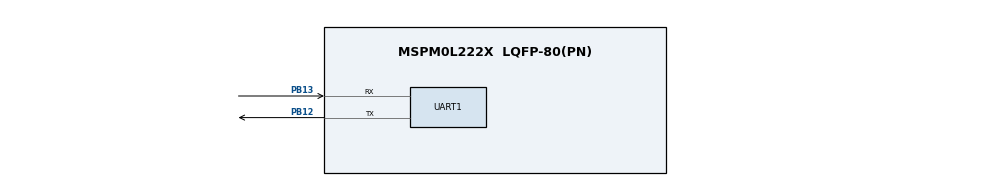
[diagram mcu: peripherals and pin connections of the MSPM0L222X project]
/**
 * @cliArgs --device "MSPM0L222X" --part "Default" --package "LQFP-80(PN)" --product "mspm0_sdk@2.05.00.05"
 * @versions {"tool":"1.24.0+4110"}
 */

/**
 * Import the modules used in this configuration.
 */
const GPIO   = scripting.addModule("/ti/driverlib/GPIO", {}, false);
const GPIO1  = GPIO.addInstance();
const GPIO2  = GPIO.addInstance();
const SYSCTL = scripting.addModule("/ti/driverlib/SYSCTL");
const UART   = scripting.addModule("/ti/driverlib/UART", {}, false);
const UART1  = UART.addInstance();

/**
 * Write custom configuration values to the imported modules.
 */
GPIO1.$name                          = "EXT_OUT";
GPIO1.associatedPins.create(2);
GPIO1.associatedPins[0].assignedPort = "PORTA";
GPIO1.associatedPins[0].assignedPin  = "0";
GPIO1.associatedPins[0].$name        = "LED_3";
GPIO1.associatedPins[1].$name        = "RGB_LED";

const Board = scripting.addModule("/ti/driverlib/Board", {}, false);

GPIO2.$name                         = "EXT_IN";
GPIO2.port                          = "PORTA";
GPIO2.associatedPins.create(2);
GPIO2.associatedPins[0].$name       = "SWITCH";
GPIO2.associatedPins[0].direction   = "INPUT";
GPIO2.associatedPins[0].assignedPin = "8";
GPIO2.associatedPins[0].interruptEn = true;
GPIO2.associatedPins[0].polarity    = "RISE";
GPIO2.associatedPins[1].$name       = "SWITCH_2";
GPIO2.associatedPins[1].assignedPin = "18";
GPIO2.associatedPins[1].direction   = "INPUT";
GPIO2.associatedPins[1].interruptEn = true;
GPIO2.associatedPins[1].polarity    = "RISE";


UART1.$name                            = "DEBUG_UART";
UART1.enabledInterrupts                = ["RX"];
UART1.targetBaudRate                   = 115200;
UART1.peripheral.rxPin.$assign         = "PB13";
UART1.peripheral.txPin.$assign         = "PB12";
UART1.txPinConfig.$name                = "ti_driverlib_gpio_GPIOPinGeneric0";
UART1.txPinConfig.direction            = scripting.forceWrite("OUTPUT");
UART1.txPinConfig.hideOutputInversion  = scripting.forceWrite(false);
UART1.txPinConfig.onlyInternalResistor = scripting.forceWrite(false);
UART1.txPinConfig.passedPeripheralType = scripting.forceWrite("Digital");
UART1.rxPinConfig.$name                = "ti_driverlib_gpio_GPIOPinGeneric1";
UART1.rxPinConfig.hideOutputInversion  = scripting.forceWrite(false);
UART1.rxPinConfig.onlyInternalResistor = scripting.forceWrite(false);
UART1.rxPinConfig.passedPeripheralType = scripting.forceWrite("Digital");

/**
 * Pinmux solution for unlocked pins/peripherals. This ensures that minor changes to the automatic solver in a future
 * version of the tool will not impact the pinmux you originally saw.  These lines can be completely deleted in order to
 * re-solve from scratch.
 */
GPIO1.associatedPins[0].pin.$suggestSolution = "PA0";
GPIO1.associatedPins[1].pin.$suggestSolution = "PA1";
Board.peripheral.$suggestSolution            = "DEBUGSS";
Board.peripheral.swclkPin.$suggestSolution   = "PA20";
Board.peripheral.swdioPin.$suggestSolution   = "PA19";
GPIO2.associatedPins[0].pin.$suggestSolution = "PA8";
GPIO2.associatedPins[1].pin.$suggestSolution = "PA18";
SYSCTL.peripheral.$suggestSolution           = "SYSCTL";
UART1.peripheral.$suggestSolution            = "UART3";
